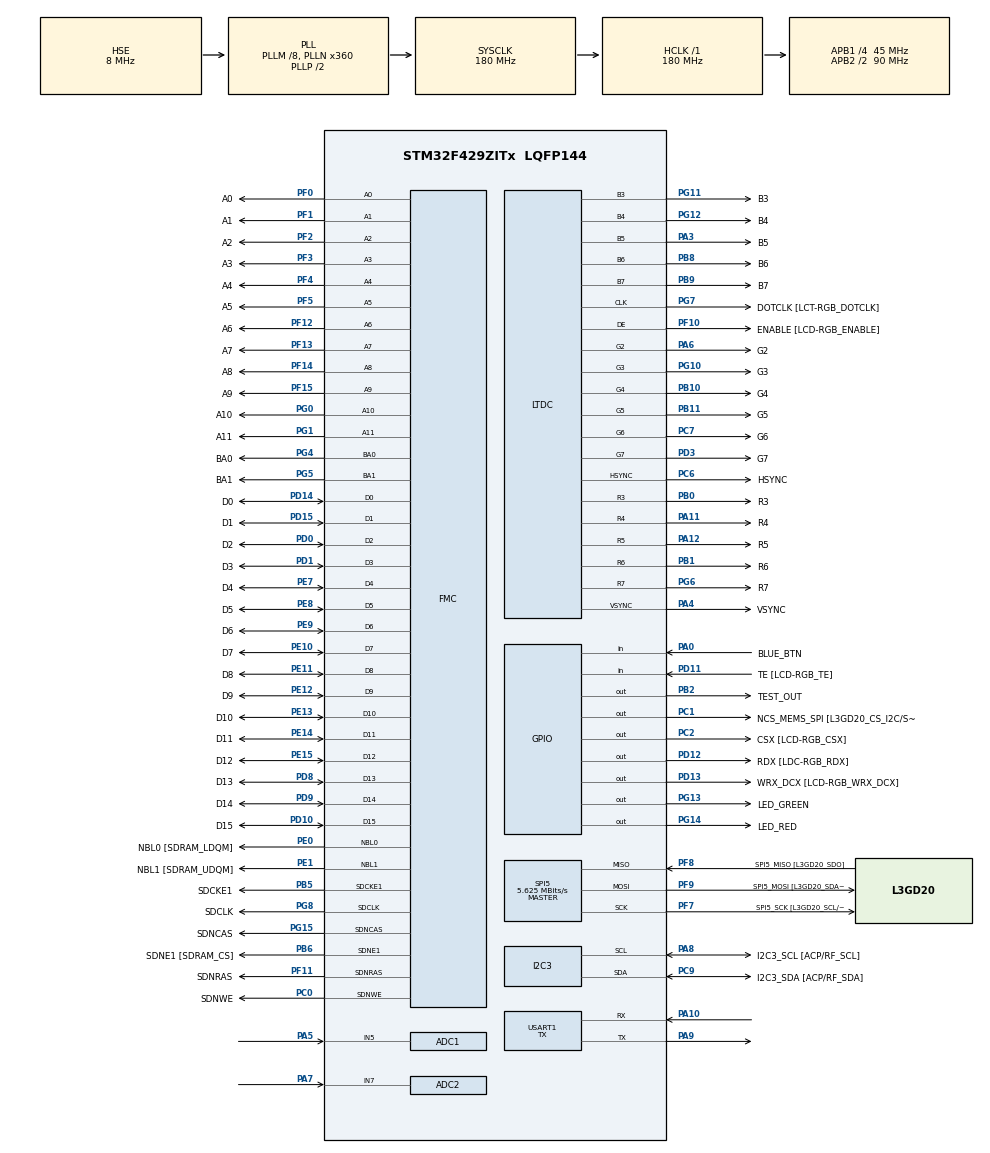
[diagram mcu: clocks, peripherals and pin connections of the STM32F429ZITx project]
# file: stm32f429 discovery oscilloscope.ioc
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PF5.GPIO_PuPd=GPIO_NOPULL
VP_TIM5_VS_ClockSourceINT.Mode=Internal
PD12.GPIO_Label=RDX [LDC-RGB_RDX]
PC10.GPIO_PuPd=GPIO_NOPULL
FMC.SDClockPeriod2=FMC_SDRAM_CLOCK_PERIOD_2
FMC.SDClockPeriod1=FMC_SDRAM_CLOCK_PERIOD_2
SH.FMC_A0.0=FMC_A0,12b-sda1
PB10.GPIO_PuPd=GPIO_NOPULL
PG8.Signal=FMC_SDCLK
PG0.Signal=FMC_A10
PA3.GPIO_PuPd=GPIO_NOPULL
PE10.GPIO_PuPd=GPIO_NOPULL
PD10.GPIO_PuPd=GPIO_NOPULL
SH.FMC_D5_DA5.0=FMC_D5,sd-16b-d1
PF10.GPIO_PuPd=GPIO_NOPULL
PG10.GPIO_PuPd=GPIO_NOPULL
PA6.GPIO_Mode=GPIO_MODE_AF_PP
SH.FMC_D9_DA9.0=FMC_D9,sd-16b-d1
PG13.GPIO_Mode=GPIO_MODE_OUTPUT_PP
PE13.GPIO_Mode=GPIO_MODE_AF_PP
PF13.GPIO_Mode=GPIO_MODE_AF_PP
PG15.GPIO_Label=SDNCAS
PA4.Mode=RGB565
PF7.Signal=SPI5_SCK
PD13.GPIO_Mode=GPIO_MODE_OUTPUT_PP
NVIC.DMA2D_IRQn=true\:5\:0\:true\:false\:true\:true\:true
SH.FMC_SDNWE.0=FMC_SDNWE,12b-sda1
SH.FMC_D11_DA11.0=FMC_D11,sd-16b-d1
PG7.GPIO_Mode=GPIO_MODE_AF_PP
RCC.APB2TimFreq_Value=180000000
PB6.Signal=FMC_SDNE1
Dma.ADC1.0.Direction=DMA_PERIPH_TO_MEMORY
PC7.Signal=LTDC_G6
PD0.Signal=FMC_D2_DA2
PD8.Signal=FMC_D13_DA13
PE1.Signal=FMC_NBL1
ADC2.EOCSelection=ADC_EOC_SEQ_CONV
Dma.ADC1.0.MemDataAlignment=DMA_MDATAALIGN_WORD
PF1.GPIO_Label=A1
PC1.GPIO_PuPd=GPIO_NOPULL
PD1.GPIO_Label=D3
FMC.SelfRefreshTime1=4
PF12.GPIO_Label=A6
LTDC.PixelFormat_L0=LTDC_PIXEL_FORMAT_RGB565
LTDC.PixelFormat_L1=LTDC_PIXEL_FORMAT_RGB565
PB1.GPIO_Speed=GPIO_SPEED_FREQ_LOW
PE9.Signal=FMC_D6_DA6
PD1.GPIO_Speed=GPIO_SPEED_FREQ_VERY_HIGH
SH.FMC_A2.0=FMC_A2,12b-sda1
PB1.GPIO_Label=R6
PG4.GPIO_Label=BA0
PC9.Mode=I2C
PD14.GPIO_PuPd=GPIO_NOPULL
PA8.Signal=I2C3_SCL
SH.FMC_D1_DA1.0=FMC_D1,sd-16b-d1
PF1.GPIO_Speed=GPIO_SPEED_FREQ_VERY_HIGH
PF1.GPIO_Mode=GPIO_MODE_AF_PP
LTDC.HSync=10
PF14.GPIO_PuPd=GPIO_NOPULL
PG0.GPIO_PuPd=GPIO_NOPULL
PE9.GPIO_Mode=GPIO_MODE_AF_PP
Mcu.Package=LQFP144
PB9.Signal=LTDC_B7
PB1.Signal=LTDC_R6
PD12.Signal=GPIO_Output
ADC2.Channel-1\#ChannelRegularConversion=ADC_CHANNEL_7
PA10.Signal=USART1_RX
PB9.GPIO_PuPd=GPIO_NOPULL
PE12.GPIO_Label=D9
FMC.WriteRecoveryTime1=3
PE12.GPIO_Speed=GPIO_SPEED_FREQ_VERY_HIGH
PB5.GPIO_Speed=GPIO_SPEED_FREQ_VERY_HIGH
SPI5.CalculateBaudRate=5.625 MBits/s
PE8.GPIO_Speed=GPIO_SPEED_FREQ_VERY_HIGH
PG8.GPIO_Speed=GPIO_SPEED_FREQ_VERY_HIGH
RCC.APB2CLKDivider=RCC_HCLK_DIV2
LTDC.VSync=2
PF5.GPIO_Speed=GPIO_SPEED_FREQ_VERY_HIGH
RCC.APB1TimFreq_Value=90000000
FMC.RowCycleDelay2=7
PF10.Mode=RGB565
FMC.RowCycleDelay1=7
PD3.GPIO_PuPd=GPIO_NOPULL
PF9.GPIO_PuPd=GPIO_NOPULL
PA4.GPIO_Label=VSYNC
PA8.GPIO_Speed=GPIO_SPEED_FREQ_LOW
ADC1.EOCSelection=ADC_EOC_SEQ_CONV
PD15.Signal=FMC_D1_DA1
ADC2.DMAAccessMode=ADC_DMAACCESSMODE_2
PG12.Signal=LTDC_B4
PB5.GPIO_Mode=GPIO_MODE_AF_PP
SH.FMC_A4.0=FMC_A4,12b-sda1
PF4.GPIO_Mode=GPIO_MODE_AF_PP
PG5.Signal=FMC_A15_BA1
SH.FMC_D10_DA10.0=FMC_D10,sd-16b-d1
PB6.GPIO_PuPd=GPIO_NOPULL
PD3.Signal=LTDC_G7
PC2.Signal=GPIO_Output
PF5.GPIO_Mode=GPIO_MODE_AF_PP
LTDC.ImageWidth_L1=240
PG8.GPIO_PuPd=GPIO_NOPULL
PF8.GPIO_Label=SPI5_MISO [L3GD20_SDO]
LTDC.ImageWidth_L0=240
PD10.Signal=FMC_D15_DA15
PA3.Mode=RGB565
PC10.GPIO_Mode=GPIO_MODE_AF_PP
PB8.GPIO_Label=B6
PB10.GPIO_Mode=GPIO_MODE_AF_PP
PA8.GPIO_Label=I2C3_SCL [ACP/RF_SCL]
PE8.GPIO_Label=D5
Dma.ADC1.0.Priority=DMA_PRIORITY_VERY_HIGH
PB1.GPIO_Mode=GPIO_MODE_AF_PP
PG10.GPIO_Mode=GPIO_MODE_AF_PP
PA5.Signal=ADCx_IN5
PF10.GPIO_Mode=GPIO_MODE_AF_PP
PE1.GPIO_Label=NBL1 [SDRAM_UDQM]
PF15.GPIO_Speed=GPIO_SPEED_FREQ_VERY_HIGH
PF13.GPIO_PuPd=GPIO_NOPULL
FMC.ReadBurst1=FMC_SDRAM_RBURST_DISABLE
SH.FMC_A6.0=FMC_A6,12b-sda1
PE14.Signal=FMC_D11_DA11
PF12.GPIO_Speed=GPIO_SPEED_FREQ_VERY_HIGH
PG7.GPIO_Label=DOTCLK [LCT-RGB_DOTCLK]
PF4.GPIO_Label=A4
PC9.GPIO_PuPd=GPIO_NOPULL
PC1.GPIO_Speed=GPIO_SPEED_FREQ_LOW
PF13.Signal=FMC_A7
PG14.GPIO_PuPd=GPIO_NOPULL
PG1.GPIO_Speed=GPIO_SPEED_FREQ_VERY_HIGH
ADC1.ExternalTrigConv=ADC_EXTERNALTRIGCONV_T2_TRGO
PC7.GPIO_Label=G6
ADC1.master=1
ADC2.NbrOfConversionFlag=1
PB5.GPIO_PuPd=GPIO_NOPULL
ProjectManager.HeapSize=0x10
PB1.Mode=RGB565
PD0.GPIO_PuPd=GPIO_NOPULL
PG12.GPIO_Speed=GPIO_SPEED_FREQ_LOW
PD8.GPIO_Speed=GPIO_SPEED_FREQ_VERY_HIGH
NVIC.PriorityGroup=NVIC_PRIORITYGROUP_4
PF0.GPIO_Label=A0
PE15.GPIO_Speed=GPIO_SPEED_FREQ_VERY_HIGH
PF4.Signal=FMC_A4
PD14.GPIO_Mode=GPIO_MODE_AF_PP
PG5.GPIO_Speed=GPIO_SPEED_FREQ_VERY_HIGH
Mcu.Family=STM32F4
LTDC.BlendingFactor1_L1=LTDC_BLENDING_FACTOR1_PAxCA
LTDC.BlendingFactor1_L0=LTDC_BLENDING_FACTOR1_CA
PA6.Mode=RGB565
SH.FMC_A8.0=FMC_A8,12b-sda1
SH.FMC_D14_DA14.0=FMC_D14,sd-16b-d1
PE11.GPIO_Label=D8
PD9.GPIO_Speed=GPIO_SPEED_FREQ_VERY_HIGH
PD0.GPIO_Label=D2
PA11.Mode=RGB565
PF9.GPIO_Speed=GPIO_SPEED_FREQ_LOW
PC2.GPIO_Speed=GPIO_SPEED_FREQ_LOW
SH.FMC_A14_BA0.0=FMC_BA0,FourSdramBanks1
SH.FMC_A11.0=FMC_A11,12b-sda1
PD8.GPIO_PuPd=GPIO_NOPULL
PG5.GPIO_Label=BA1
PG11.Signal=LTDC_B3
PG15.Signal=FMC_SDNCAS
PD13.Signal=GPIO_Output
PE11.GPIO_PuPd=GPIO_NOPULL
PF11.GPIO_PuPd=GPIO_NOPULL
ADC1.Mode=ADC_DUALMODE_REGSIMULT
PB1.GPIO_PuPd=GPIO_NOPULL
PF13.GPIO_Speed=GPIO_SPEED_FREQ_VERY_HIGH
LTDC.WindowX1_L1=240
SH.FMC_NBL1.0=FMC_NBL1,Sd2ByteEnable1
LTDC.WindowX1_L0=240
PG5.GPIO_PuPd=GPIO_NOPULL
ADC1.Channel-0\#ChannelRegularConversion=ADC_CHANNEL_5
RCC.HSE_VALUE=8000000
PA4.GPIO_PuPd=GPIO_NOPULL
FMC.ExitSelfRefreshDelay1=7
PF7.GPIO_Mode=GPIO_MODE_AF_PP
PE13.GPIO_PuPd=GPIO_NOPULL
PA4.GPIO_Speed=GPIO_SPEED_FREQ_LOW
PG11.GPIO_Speed=GPIO_SPEED_FREQ_LOW
PH1/OSC_OUT.GPIO_Label=PH1-OSC_OUT
PA6.GPIO_PuPd=GPIO_NOPULL
PF9.Mode=Full_Duplex_Master
PF7.GPIO_Speed=GPIO_SPEED_FREQ_LOW
PF8.GPIO_PuPd=GPIO_NOPULL
PF11.Signal=FMC_SDNRAS
PB5.Mode=SdramChipSelect2_1
PC7.GPIO_Mode=GPIO_MODE_AF_PP
PG7.GPIO_PuPd=GPIO_NOPULL
PD10.GPIO_Speed=GPIO_SPEED_FREQ_VERY_HIGH
PG4.GPIO_Mode=GPIO_MODE_AF_PP
PD6.GPIO_Mode=GPIO_MODE_AF_PP
PD13.GPIO_Label=WRX_DCX [LCD-RGB_WRX_DCX]
PA6.Signal=LTDC_G2
PB0.GPIO_Mode=GPIO_MODE_AF_PP
RCC.EnbaleCSS=true
PG1.GPIO_PuPd=GPIO_NOPULL
PF8.Signal=SPI5_MISO
PG0.GPIO_Label=A10
PB5.GPIO_Label=SDCKE1
PD0.GPIO_Mode=GPIO_MODE_AF_PP
PG14.GPIO_Mode=GPIO_MODE_OUTPUT_PP
PG11.GPIO_Label=B3
PD3.GPIO_Label=G7
PE14.GPIO_Mode=GPIO_MODE_AF_PP
PE7.Signal=FMC_D4_DA4
PD6.Signal=LTDC_B2
Dma.Request0=ADC1
PF3.GPIO_Label=A3
PA12.GPIO_Speed=GPIO_SPEED_FREQ_LOW
PA3.Signal=LTDC_B5
PE0.GPIO_PuPd=GPIO_NOPULL
PG1.GPIO_Mode=GPIO_MODE_AF_PP
NVIC.LTDC_IRQn=true\:5\:0\:true\:false\:true\:true\:true
LTDC.VFP=4
PD15.GPIO_Label=D1
LTDC.WindowY1_L0=320
PG7.Signal=LTDC_CLK
LTDC.WindowY1_L1=320
PA10.Mode=Asynchronous
PC9.GPIO_Label=I2C3_SDA [ACP/RF_SDA]
PF10.GPIO_Speed=GPIO_SPEED_FREQ_LOW
PE14.GPIO_Label=D11
PD9.Signal=FMC_D14_DA14
SPI5.Mode=SPI_MODE_MASTER
PA12.GPIO_Label=R5
PD8.GPIO_Label=D13
PB0.GPIO_Speed=GPIO_SPEED_FREQ_LOW
PG8.GPIO_Label=SDCLK
Dma.ADC1.0.PeriphDataAlignment=DMA_PDATAALIGN_WORD
PA9.Mode=Asynchronous
PB2/BOOT1.Signal=GPIO_Output
PB10.GPIO_Label=G4
PC9.GPIO_Mode=GPIO_MODE_AF_OD
SH.FMC_D13_DA13.0=FMC_D13,sd-16b-d1
PA3.GPIO_Mode=GPIO_MODE_AF_PP
PG0.GPIO_Speed=GPIO_SPEED_FREQ_VERY_HIGH
PB9.Mode=RGB565
PF9.GPIO_Label=SPI5_MOSI [L3GD20_SDA/SDI/SDO]
PD10.GPIO_Label=D15
PE10.GPIO_Mode=GPIO_MODE_AF_PP
board=STM32F429I-DISC1
PD13.GPIO_Speed=GPIO_SPEED_FREQ_LOW
PG12.Mode=RGB565
PC7.GPIO_Speed=GPIO_SPEED_FREQ_LOW
RCC.VCOOutputFreq_Value=360000000
ADC1.EnableAnalogWatchDog=true
PA4.GPIO_Mode=GPIO_MODE_AF_PP
PF4.GPIO_Speed=GPIO_SPEED_FREQ_VERY_HIGH
PC1.GPIO_Label=NCS_MEMS_SPI [L3GD20_CS_I2C/SPI]
PE11.GPIO_Mode=GPIO_MODE_AF_PP
SH.FMC_D12_DA12.0=FMC_D12,sd-16b-d1
PF15.GPIO_Label=A9
PE14.GPIO_PuPd=GPIO_NOPULL
PF1.Signal=FMC_A1
PF8.GPIO_Mode=GPIO_MODE_AF_PP
PE0.Signal=FMC_NBL0
PE7.GPIO_Label=D4
PE12.Signal=FMC_D9_DA9
PE12.GPIO_Mode=GPIO_MODE_AF_PP
RCC.48MHZClocksFreq_Value=120000000
RCC.SYSCLKFreq_VALUE=180000000
TIM5.Prescaler=99
Dma.ADC1.0.MemInc=DMA_MINC_ENABLE
PE15.GPIO_PuPd=GPIO_NOPULL
PG4.GPIO_PuPd=GPIO_NOPULL
PD3.GPIO_Mode=GPIO_MODE_AF_PP
RCC.HSI_VALUE=16000000
PA8.GPIO_PuPd=GPIO_NOPULL
PH0/OSC_IN.GPIO_Label=PH0-OSC_IN
PF9.GPIO_Mode=GPIO_MODE_AF_PP
RCC.PLLQ=3
RCC.PLLM=8
RCC.PLLN=360
ADC2.Rank-1\#ChannelRegularConversion=1
TIM5.Period=44
PG0.GPIO_Mode=GPIO_MODE_AF_PP
PB8.GPIO_Speed=GPIO_SPEED_FREQ_LOW
PD6.GPIO_Speed=GPIO_SPEED_FREQ_LOW
PG14.GPIO_Speed=GPIO_SPEED_FREQ_LOW
LTDC.ImageHeight_L0=320
LTDC.ImageHeight_L1=320
PB0.GPIO_PuPd=GPIO_NOPULL
PA3.GPIO_Label=B5
PD6.GPIO_PuPd=GPIO_NOPULL
PA11.GPIO_Speed=GPIO_SPEED_FREQ_LOW
PF15.GPIO_Mode=GPIO_MODE_AF_PP
SH.FMC_D7_DA7.0=FMC_D7,sd-16b-d1
PE15.GPIO_Mode=GPIO_MODE_AF_PP
PD1.GPIO_Mode=GPIO_MODE_AF_PP
PD15.GPIO_Mode=GPIO_MODE_AF_PP
PE14.GPIO_Speed=GPIO_SPEED_FREQ_VERY_HIGH
FMC.RCDDelay1=2
ADC2.SamplingTime-1\#ChannelRegularConversion=ADC_SAMPLETIME_3CYCLES
PB10.Mode=RGB565
PA8.GPIO_Mode=GPIO_MODE_AF_OD
PG4.Signal=FMC_A14_BA0
PG6.GPIO_Label=R7
PE8.GPIO_PuPd=GPIO_NOPULL
FMC.LoadToActiveDelay1=2
PC6.GPIO_Label=HSYNC
PA6.GPIO_Label=G2
PB6.GPIO_Label=SDNE1 [SDRAM_CS]
PA3.GPIO_Speed=GPIO_SPEED_FREQ_LOW
PD3.GPIO_Speed=GPIO_SPEED_FREQ_LOW
PG6.Mode=RGB565
PD6.GPIO_Label=B2
PG13.Signal=GPIO_Output
RCC.SYSCLKSource=RCC_SYSCLKSOURCE_PLLCLK
PG15.GPIO_Mode=GPIO_MODE_AF_PP
PB11.GPIO_Speed=GPIO_SPEED_FREQ_LOW
SH.FMC_A15_BA1.0=FMC_BA1,FourSdramBanks1
PD14.GPIO_Speed=GPIO_SPEED_FREQ_VERY_HIGH
NVIC.TIM5_IRQn=true\:0\:0\:false\:false\:true\:true\:true
PB2/BOOT1.GPIO_Label=TEST_OUT
PH1/OSC_OUT.Signal=RCC_OSC_OUT
PB6.Mode=SdramChipSelect2_1
PF10.GPIO_Label=ENABLE [LCD-RGB_ENABLE]
PF14.GPIO_Speed=GPIO_SPEED_FREQ_VERY_HIGH
PG6.GPIO_PuPd=GPIO_NOPULL
PF11.GPIO_Mode=GPIO_MODE_AF_PP
Dma.ADC1.0.PeriphInc=DMA_PINC_DISABLE
PD11.GPIO_Mode=GPIO_MODE_INPUT
PF8.Mode=Full_Duplex_Master
PF3.Signal=FMC_A3
PD3.Mode=RGB565
PE10.Signal=FMC_D7_DA7
ADC1.SamplingTime-0\#ChannelRegularConversion=ADC_SAMPLETIME_3CYCLES
PF3.GPIO_Speed=GPIO_SPEED_FREQ_VERY_HIGH
PF3.GPIO_PuPd=GPIO_NOPULL
PC6.GPIO_PuPd=GPIO_NOPULL
SH.FMC_A1.0=FMC_A1,12b-sda1
SH.FMC_SDCLK.0=FMC_SDCLK,12b-sda1
PC2.GPIO_Mode=GPIO_MODE_OUTPUT_PP
PG12.GPIO_PuPd=GPIO_NOPULL
PF14.Signal=FMC_A8
VP_DMA2D_VS_DMA2D.Mode=DMA2D_Activate
Dma.ADC1.0.FIFOMode=DMA_FIFOMODE_DISABLE
PA6.GPIO_Speed=GPIO_SPEED_FREQ_LOW
PB11.GPIO_Mode=GPIO_MODE_AF_PP
PA12.GPIO_PuPd=GPIO_NOPULL
PE10.GPIO_Label=D7
PD9.GPIO_PuPd=GPIO_NOPULL
PC6.GPIO_Speed=GPIO_SPEED_FREQ_LOW
SH.FMC_D3_DA3.0=FMC_D3,sd-16b-d1
SPI5.VirtualType=VM_MASTER
PG6.GPIO_Speed=GPIO_SPEED_FREQ_LOW
PE12.GPIO_PuPd=GPIO_NOPULL
PD8.GPIO_Mode=GPIO_MODE_AF_PP
Dma.ADC1.0.Instance=DMA2_Stream0
ADC1.Rank-0\#ChannelRegularConversion=1
PD9.GPIO_Label=D14
PE11.GPIO_Speed=GPIO_SPEED_FREQ_VERY_HIGH
PD9.GPIO_Mode=GPIO_MODE_AF_PP
PB8.GPIO_PuPd=GPIO_NOPULL
PC6.Signal=LTDC_HSYNC
PB11.GPIO_Label=G5
PD1.Signal=FMC_D3_DA3
PA11.GPIO_Label=R4
PE1.GPIO_PuPd=GPIO_NOPULL
PF14.GPIO_Label=A8
PD1.GPIO_PuPd=GPIO_NOPULL
PC0.Signal=FMC_SDNWE
RCC.APB1CLKDivider=RCC_HCLK_DIV4
PF13.GPIO_Label=A7
PG13.GPIO_Label=LED_GREEN
PD0.GPIO_Speed=GPIO_SPEED_FREQ_VERY_HIGH
PG10.Signal=LTDC_G3
PE0.GPIO_Speed=GPIO_SPEED_FREQ_VERY_HIGH
PF11.GPIO_Speed=GPIO_SPEED_FREQ_VERY_HIGH
SH.FMC_A3.0=FMC_A3,12b-sda1
TIM5.TIM_MasterOutputTrigger=TIM_TRGO_UPDATE
FMC.CASLatency1=FMC_SDRAM_CAS_LATENCY_3
PF2.GPIO_Mode=GPIO_MODE_AF_PP
PB11.Mode=RGB565
SH.FMC_D15_DA15.0=FMC_D15,sd-16b-d1
SH.ADCx_IN7.0=ADC2_IN7,IN7
PC6.Mode=RGB565
PA9.Signal=USART1_TX
PC7.GPIO_PuPd=GPIO_NOPULL
PE9.GPIO_Label=D6
PB10.Signal=LTDC_G4
PE7.GPIO_Speed=GPIO_SPEED_FREQ_VERY_HIGH
PE15.Signal=FMC_D12_DA12
PG11.GPIO_Mode=GPIO_MODE_AF_PP
USART1.Mode=MODE_TX
PE8.Signal=FMC_D5_DA5
PG5.GPIO_Mode=GPIO_MODE_AF_PP
PA0/WKUP.GPIO_Label=BLUE_BTN
PC6.GPIO_Mode=GPIO_MODE_AF_PP
ADC1.DMAContinuousRequests=ENABLE
PG14.GPIO_Label=LED_RED
SH.FMC_SDNCAS.0=FMC_SDNCAS,12b-sda1
PG12.GPIO_Mode=GPIO_MODE_AF_PP
PF7.GPIO_PuPd=GPIO_NOPULL
PA4.Signal=LTDC_VSYNC
PB5.Signal=FMC_SDCKE1
PE13.GPIO_Label=D10
PD11.Signal=GPIO_Input
USART1.VirtualMode=VM_ASYNC
SH.FMC_A5.0=FMC_A5,12b-sda1
PG11.Mode=RGB565
LTDC.Alpha_L0=255
PA11.Signal=LTDC_R4
PF9.Signal=SPI5_MOSI
SH.ADCx_IN5.0=ADC1_IN5,IN5
PC9.GPIO_Speed=GPIO_SPEED_FREQ_LOW
PB8.Mode=RGB565
PF12.GPIO_PuPd=GPIO_NOPULL
TIM2.AutoReloadPreload=TIM_AUTORELOAD_PRELOAD_ENABLE
PA8.Mode=I2C
PB6.GPIO_Speed=GPIO_SPEED_FREQ_VERY_HIGH
PG6.GPIO_Mode=GPIO_MODE_AF_PP
PB0.Signal=LTDC_R3
PE0.GPIO_Mode=GPIO_MODE_AF_PP
PC1.Signal=GPIO_Output
PF3.GPIO_Mode=GPIO_MODE_AF_PP
PG10.GPIO_Label=G3
PG15.GPIO_PuPd=GPIO_NOPULL
PE7.GPIO_PuPd=GPIO_NOPULL
RCC.CortexFreq_Value=180000000
PG6.Signal=LTDC_R7
PB10.GPIO_Speed=GPIO_SPEED_FREQ_LOW
PB6.GPIO_Mode=GPIO_MODE_AF_PP
RCC.PLLSAIDivR=RCC_PLLSAIDIVR_8
LTDC.HBP=20
PD15.GPIO_Speed=GPIO_SPEED_FREQ_VERY_HIGH
PC10.Signal=LTDC_R2
PF4.GPIO_PuPd=GPIO_NOPULL
SH.FMC_NBL0.0=FMC_NBL0,Sd2ByteEnable1
SH.FMC_D6_DA6.0=FMC_D6,sd-16b-d1
PC0.GPIO_Label=SDNWE
PE9.GPIO_Speed=GPIO_SPEED_FREQ_VERY_HIGH
PA0/WKUP.Signal=GPIO_Input
PB0.GPIO_Label=R3
PC10.GPIO_Speed=GPIO_SPEED_FREQ_LOW
PA11.GPIO_PuPd=GPIO_NOPULL
PB11.GPIO_PuPd=GPIO_NOPULL
PB11.Signal=LTDC_G5
PG8.GPIO_Mode=GPIO_MODE_AF_PP
PF2.GPIO_Speed=GPIO_SPEED_FREQ_VERY_HIGH
ProjectManager.StackSize=0x10
PD11.GPIO_PuPd=GPIO_NOPULL
SH.FMC_A7.0=FMC_A7,12b-sda1
PA12.Signal=LTDC_R5
PE1.GPIO_Mode=GPIO_MODE_AF_PP
PH0/OSC_IN.Mode=HSE-External-Oscillator
PG11.GPIO_PuPd=GPIO_NOPULL
PD11.GPIO_Label=TE [LCD-RGB_TE]
RCC.HCLKFreq_Value=180000000
PF11.GPIO_Label=SDNRAS
PF2.GPIO_PuPd=GPIO_NOPULL
PF12.Signal=FMC_A6
NVIC.DMA2_Stream0_IRQn=true\:0\:0\:false\:false\:true\:false\:true
SH.FMC_A10.0=FMC_A10,12b-sda1
RCC.AHBFreq_Value=180000000
PC1.GPIO_Mode=GPIO_MODE_OUTPUT_PP
SH.FMC_D8_DA8.0=FMC_D8,sd-16b-d1
FMC.RPDelay2=2
FMC.RPDelay1=2
PG13.GPIO_PuPd=GPIO_NOPULL
SH.FMC_D2_DA2.0=FMC_D2,sd-16b-d1
PE13.Signal=FMC_D10_DA10
PF7.GPIO_Label=SPI5_SCK [L3GD20_SCL/SPC]
PG4.GPIO_Speed=GPIO_SPEED_FREQ_VERY_HIGH
LTDC.HFP=10
LTDC.BlendingFactor2_L0=LTDC_BLENDING_FACTOR2_CA
LTDC.BlendingFactor2_L1=LTDC_BLENDING_FACTOR2_PAxCA
FMC.ReadPipeDelay1=FMC_SDRAM_RPIPE_DELAY_1
FMC.ReadPipeDelay2=FMC_SDRAM_RPIPE_DELAY_1
PE10.GPIO_Speed=GPIO_SPEED_FREQ_VERY_HIGH
SH.FMC_SDNRAS.0=FMC_SDNRAS,12b-sda1
DMA2D.ColorMode=DMA2D_OUTPUT_RGB565
LTDC.ActiveW=240
PH1/OSC_OUT.Mode=HSE-External-Oscillator
PF12.GPIO_Mode=GPIO_MODE_AF_PP
PD12.GPIO_Mode=GPIO_MODE_OUTPUT_PP
SPI5.BaudRatePrescaler=SPI_BAUDRATEPRESCALER_16
SH.FMC_D0_DA0.0=FMC_D0,sd-16b-d1
PG15.GPIO_Speed=GPIO_SPEED_FREQ_VERY_HIGH
PF15.GPIO_PuPd=GPIO_NOPULL
PD15.GPIO_PuPd=GPIO_NOPULL
PF5.GPIO_Label=A5
SH.FMC_A9.0=FMC_A9,12b-sda1
SH.FMC_D4_DA4.0=FMC_D4,sd-16b-d1
PE8.GPIO_Mode=GPIO_MODE_AF_PP
PE0.GPIO_Label=NBL0 [SDRAM_LDQM]
RCC.PLLSAIN=192
PF5.Signal=FMC_A5
RCC.PLLSAIR=4
TIM2.TIM_MasterOutputTrigger=TIM_TRGO_UPDATE
PB9.GPIO_Speed=GPIO_SPEED_FREQ_LOW
PG13.GPIO_Speed=GPIO_SPEED_FREQ_LOW
PF0.Signal=FMC_A0
PC0.GPIO_PuPd=GPIO_NOPULL
PC2.GPIO_Label=CSX [LCD-RGB_CSX]
PF0.GPIO_Mode=GPIO_MODE_AF_PP
ADC2.ClockPrescaler=ADC_CLOCK_SYNC_PCLK_DIV4
RCC.PLLSourceVirtual=RCC_PLLSOURCE_HSE
I2C3.I2C_Mode=I2C_Fast
LTDC.FBStartAdress_L0=0xD0000000
LTDC.FBStartAdress_L1=0xD0025800
PD12.GPIO_Speed=GPIO_SPEED_FREQ_LOW
ADC2.Mode=ADC_DUALMODE_REGSIMULT
PB9.GPIO_Label=B7
PC10.GPIO_Label=R2
PG1.Signal=FMC_A11
PG10.Mode=RGB565
PG10.GPIO_Speed=GPIO_SPEED_FREQ_LOW
PF0.GPIO_Speed=GPIO_SPEED_FREQ_VERY_HIGH
PD10.GPIO_Mode=GPIO_MODE_AF_PP
PF7.Mode=Full_Duplex_Master
PC0.GPIO_Speed=GPIO_SPEED_FREQ_VERY_HIGH
PE15.GPIO_Label=D12
ProjectManager.TargetToolchain=STM32CubeIDE
Dma.ADC1.0.Mode=DMA_CIRCULAR
LTDC.ActiveH=320
PF2.Signal=FMC_A2
PE11.Signal=FMC_D8_DA8
PG7.Mode=RGB565
RCC.LSE_VALUE=32768
PE7.GPIO_Mode=GPIO_MODE_AF_PP
PG14.Signal=GPIO_Output
PB0.Mode=RGB565
PG1.GPIO_Label=A11
PB9.GPIO_Mode=GPIO_MODE_AF_PP
PA12.GPIO_Mode=GPIO_MODE_AF_PP
PH0/OSC_IN.Signal=RCC_OSC_IN
PG7.GPIO_Speed=GPIO_SPEED_FREQ_LOW
RCC.APB2Freq_Value=90000000
PC0.GPIO_Mode=GPIO_MODE_AF_PP
LTDC.Layers=1
VP_TIM2_VS_ClockSourceINT.Mode=Internal
PF10.Signal=LTDC_DE
PE1.GPIO_Speed=GPIO_SPEED_FREQ_VERY_HIGH
PF1.GPIO_PuPd=GPIO_NOPULL
PD13.GPIO_PuPd=GPIO_NOPULL
PF15.Signal=FMC_A9
PD14.GPIO_Label=D0
PC2.GPIO_PuPd=GPIO_NOPULL
Mcu.Name=STM32F429ZITx
PD14.Signal=FMC_D0_DA0
PF0.GPIO_PuPd=GPIO_NOPULL
PA12.Mode=RGB565
PG12.GPIO_Label=B4
ADC1.WatchdogChannel=ADC_CHANNEL_5
ADC1.NbrOfConversionFlag=1
PF8.GPIO_Speed=GPIO_SPEED_FREQ_LOW
PE13.GPIO_Speed=GPIO_SPEED_FREQ_VERY_HIGH
PB8.Signal=LTDC_B6
PF14.GPIO_Mode=GPIO_MODE_AF_PP
PC9.Signal=I2C3_SDA
PC7.Mode=RGB565
PA11.GPIO_Mode=GPIO_MODE_AF_PP
PB8.GPIO_Mode=GPIO_MODE_AF_PP
RCC.APB1Freq_Value=45000000
ADC1.ClockPrescaler=ADC_CLOCK_SYNC_PCLK_DIV4
PD12.GPIO_PuPd=GPIO_NOPULL
SPI5.Direction=SPI_DIRECTION_2LINES
PA7.Signal=ADCx_IN7
PE9.GPIO_PuPd=GPIO_NOPULL
PF2.GPIO_Label=A2

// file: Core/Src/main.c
/* USER CODE BEGIN Header */
/**
  ******************************************************************************
  * @file           : main.c
  * @brief          : Main program body
  ******************************************************************************
  * @attention
  *
  * <h2><center>&copy; Copyright (c) 2020 STMicroelectronics.
  * All rights reserved.</center></h2>
  *
  * This software component is licensed by ST under Ultimate Liberty license
  * SLA0044, the "License"; You may not use this file except in compliance with
  * the License. You may obtain a copy of the License at:
  *                             www.st.com/SLA0044
  *
  ******************************************************************************
  */
/* USER CODE END Header */
#include "main.h"

/* USER CODE BEGIN Includes */
#include "oszi.h"
#include "stm32_ub_sdram.h"
/* USER CODE END Includes */

ADC_HandleTypeDef hadc1;
ADC_HandleTypeDef hadc2;
DMA_HandleTypeDef hdma_adc1;

DMA2D_HandleTypeDef hdma2d;

I2C_HandleTypeDef hi2c3;

LTDC_HandleTypeDef hltdc;

SPI_HandleTypeDef hspi5;

TIM_HandleTypeDef htim2;
TIM_HandleTypeDef htim5;

UART_HandleTypeDef huart1;

SDRAM_HandleTypeDef hsdram1;

void SystemClock_Config(void);
static void MX_GPIO_Init(void);
static void MX_DMA_Init(void);
static void MX_DMA2D_Init(void);
static void MX_FMC_Init(void);
static void MX_I2C3_Init(void);
static void MX_LTDC_Init(void);
static void MX_ADC1_Init(void);
static void MX_ADC2_Init(void);
static void MX_TIM2_Init(void);
static void MX_SPI5_Init(void);
static void MX_TIM5_Init(void);
static void MX_USART1_UART_Init(void);

int main(void)
{
  /* USER CODE BEGIN 1 */

	// For freezing the timers when debugging (If the core halts, also do the timers)
	 __HAL_DBGMCU_FREEZE_TIM2();
	 __HAL_DBGMCU_FREEZE_TIM5();
  /* USER CODE END 1 */

  /* MCU Configuration--------------------------------------------------------*/

  /* Reset of all peripherals, Initializes the Flash interface and the Systick. */
  HAL_Init();

  /* Configure the system clock */
  SystemClock_Config();

  /* Initialize all configured peripherals */
  MX_GPIO_Init();
  MX_DMA_Init();
  MX_DMA2D_Init();
  MX_FMC_Init();
  MX_I2C3_Init();
  MX_LTDC_Init();
  MX_ADC1_Init();
  MX_ADC2_Init();
  MX_TIM2_Init();
  MX_SPI5_Init();
  MX_TIM5_Init();
  MX_USART1_UART_Init();
  /* USER CODE BEGIN 2 */
  oszi_init();
  oszi_start();
  /* USER CODE END 2 */

  /* Infinite loop */
  while (1)
{

  }
}

void SystemClock_Config(void)
{
  RCC_OscInitTypeDef RCC_OscInitStruct = {0};
  RCC_ClkInitTypeDef RCC_ClkInitStruct = {0};
  RCC_PeriphCLKInitTypeDef PeriphClkInitStruct = {0};

  /** Configure the main internal regulator output voltage
  */
  __HAL_RCC_PWR_CLK_ENABLE();
  __HAL_PWR_VOLTAGESCALING_CONFIG(PWR_REGULATOR_VOLTAGE_SCALE1);
  /** Initializes the RCC Oscillators according to the specified parameters
  * in the RCC_OscInitTypeDef structure.
  */
  RCC_OscInitStruct.OscillatorType = RCC_OSCILLATORTYPE_HSE;
  RCC_OscInitStruct.HSEState = RCC_HSE_ON;
  RCC_OscInitStruct.PLL.PLLState = RCC_PLL_ON;
  RCC_OscInitStruct.PLL.PLLSource = RCC_PLLSOURCE_HSE;
  RCC_OscInitStruct.PLL.PLLM = 8;
  RCC_OscInitStruct.PLL.PLLN = 360;
  RCC_OscInitStruct.PLL.PLLP = RCC_PLLP_DIV2;
  RCC_OscInitStruct.PLL.PLLQ = 3;
  if (HAL_RCC_OscConfig(&RCC_OscInitStruct) != HAL_OK)
  {
    Error_Handler();
  }
  /** Activate the Over-Drive mode
  */
  if (HAL_PWREx_EnableOverDrive() != HAL_OK)
  {
    Error_Handler();
  }
  /** Initializes the CPU, AHB and APB buses clocks
  */
  RCC_ClkInitStruct.ClockType = RCC_CLOCKTYPE_HCLK|RCC_CLOCKTYPE_SYSCLK
                              |RCC_CLOCKTYPE_PCLK1|RCC_CLOCKTYPE_PCLK2;
  RCC_ClkInitStruct.SYSCLKSource = RCC_SYSCLKSOURCE_PLLCLK;
  RCC_ClkInitStruct.AHBCLKDivider = RCC_SYSCLK_DIV1;
  RCC_ClkInitStruct.APB1CLKDivider = RCC_HCLK_DIV4;
  RCC_ClkInitStruct.APB2CLKDivider = RCC_HCLK_DIV2;

  if (HAL_RCC_ClockConfig(&RCC_ClkInitStruct, FLASH_LATENCY_5) != HAL_OK)
  {
    Error_Handler();
  }
  PeriphClkInitStruct.PeriphClockSelection = RCC_PERIPHCLK_LTDC;
  PeriphClkInitStruct.PLLSAI.PLLSAIN = 192;
  PeriphClkInitStruct.PLLSAI.PLLSAIR = 4;
  PeriphClkInitStruct.PLLSAIDivR = RCC_PLLSAIDIVR_8;
  if (HAL_RCCEx_PeriphCLKConfig(&PeriphClkInitStruct) != HAL_OK)
  {
    Error_Handler();
  }
  /** Enables the Clock Security System
  */
  HAL_RCC_EnableCSS();
}

static void MX_ADC1_Init(void)
{

  ADC_MultiModeTypeDef multimode = {0};
  ADC_AnalogWDGConfTypeDef AnalogWDGConfig = {0};
  ADC_ChannelConfTypeDef sConfig = {0};

  /** Configure the global features of the ADC (Clock, Resolution, Data Alignment and number of conversion)
  */
  hadc1.Instance = ADC1;
  hadc1.Init.ClockPrescaler = ADC_CLOCK_SYNC_PCLK_DIV4;
  hadc1.Init.Resolution = ADC_RESOLUTION_12B;
  hadc1.Init.ScanConvMode = DISABLE;
  hadc1.Init.ContinuousConvMode = DISABLE;
  hadc1.Init.DiscontinuousConvMode = DISABLE;
  hadc1.Init.ExternalTrigConvEdge = ADC_EXTERNALTRIGCONVEDGE_RISING;
  hadc1.Init.ExternalTrigConv = ADC_EXTERNALTRIGCONV_T2_TRGO;
  hadc1.Init.DataAlign = ADC_DATAALIGN_RIGHT;
  hadc1.Init.NbrOfConversion = 1;
  hadc1.Init.DMAContinuousRequests = ENABLE;
  hadc1.Init.EOCSelection = ADC_EOC_SEQ_CONV;
  if (HAL_ADC_Init(&hadc1) != HAL_OK)
  {
    Error_Handler();
  }
  /** Configure the ADC multi-mode
  */
  multimode.Mode = ADC_DUALMODE_REGSIMULT;
  multimode.DMAAccessMode = ADC_DMAACCESSMODE_2;
  multimode.TwoSamplingDelay = ADC_TWOSAMPLINGDELAY_5CYCLES;
  if (HAL_ADCEx_MultiModeConfigChannel(&hadc1, &multimode) != HAL_OK)
  {
    Error_Handler();
  }
  /** Configure the analog watchdog
  */
  AnalogWDGConfig.WatchdogMode = ADC_ANALOGWATCHDOG_SINGLE_REG;
  AnalogWDGConfig.HighThreshold = 0;
  AnalogWDGConfig.LowThreshold = 0;
  AnalogWDGConfig.Channel = ADC_CHANNEL_5;
  AnalogWDGConfig.ITMode = DISABLE;
  if (HAL_ADC_AnalogWDGConfig(&hadc1, &AnalogWDGConfig) != HAL_OK)
  {
    Error_Handler();
  }
  /** Configure for the selected ADC regular channel its corresponding rank in the sequencer and its sample time.
  */
  sConfig.Channel = ADC_CHANNEL_5;
  sConfig.Rank = 1;
  sConfig.SamplingTime = ADC_SAMPLETIME_3CYCLES;
  if (HAL_ADC_ConfigChannel(&hadc1, &sConfig) != HAL_OK)
  {
    Error_Handler();
  }

}

static void MX_ADC2_Init(void)
{

  ADC_ChannelConfTypeDef sConfig = {0};

  /** Configure the global features of the ADC (Clock, Resolution, Data Alignment and number of conversion)
  */
  hadc2.Instance = ADC2;
  hadc2.Init.ClockPrescaler = ADC_CLOCK_SYNC_PCLK_DIV4;
  hadc2.Init.Resolution = ADC_RESOLUTION_12B;
  hadc2.Init.ScanConvMode = DISABLE;
  hadc2.Init.ContinuousConvMode = DISABLE;
  hadc2.Init.DiscontinuousConvMode = DISABLE;
  hadc2.Init.DataAlign = ADC_DATAALIGN_RIGHT;
  hadc2.Init.NbrOfConversion = 1;
  hadc2.Init.DMAContinuousRequests = DISABLE;
  hadc2.Init.EOCSelection = ADC_EOC_SEQ_CONV;
  if (HAL_ADC_Init(&hadc2) != HAL_OK)
  {
    Error_Handler();
  }
  /** Configure for the selected ADC regular channel its corresponding rank in the sequencer and its sample time.
  */
  sConfig.Channel = ADC_CHANNEL_7;
  sConfig.Rank = 1;
  sConfig.SamplingTime = ADC_SAMPLETIME_3CYCLES;
  if (HAL_ADC_ConfigChannel(&hadc2, &sConfig) != HAL_OK)
  {
    Error_Handler();
  }

}

static void MX_DMA2D_Init(void)
{

  hdma2d.Instance = DMA2D;
  hdma2d.Init.Mode = DMA2D_M2M;
  hdma2d.Init.ColorMode = DMA2D_OUTPUT_RGB565;
  hdma2d.Init.OutputOffset = 0;
  hdma2d.LayerCfg[1].InputOffset = 0;
  hdma2d.LayerCfg[1].InputColorMode = DMA2D_INPUT_RGB565;
  hdma2d.LayerCfg[1].AlphaMode = DMA2D_NO_MODIF_ALPHA;
  hdma2d.LayerCfg[1].InputAlpha = 0;
  if (HAL_DMA2D_Init(&hdma2d) != HAL_OK)
  {
    Error_Handler();
  }
  if (HAL_DMA2D_ConfigLayer(&hdma2d, 1) != HAL_OK)
  {
    Error_Handler();
  }

}

static void MX_I2C3_Init(void)
{

  hi2c3.Instance = I2C3;
  hi2c3.Init.ClockSpeed = 400000;
  hi2c3.Init.DutyCycle = I2C_DUTYCYCLE_2;
  hi2c3.Init.OwnAddress1 = 0;
  hi2c3.Init.AddressingMode = I2C_ADDRESSINGMODE_7BIT;
  hi2c3.Init.DualAddressMode = I2C_DUALADDRESS_DISABLE;
  hi2c3.Init.OwnAddress2 = 0;
  hi2c3.Init.GeneralCallMode = I2C_GENERALCALL_DISABLE;
  hi2c3.Init.NoStretchMode = I2C_NOSTRETCH_DISABLE;
  if (HAL_I2C_Init(&hi2c3) != HAL_OK)
  {
    Error_Handler();
  }
  /** Configure Analogue filter
  */
  if (HAL_I2CEx_ConfigAnalogFilter(&hi2c3, I2C_ANALOGFILTER_ENABLE) != HAL_OK)
  {
    Error_Handler();
  }
  /** Configure Digital filter
  */
  if (HAL_I2CEx_ConfigDigitalFilter(&hi2c3, 0) != HAL_OK)
  {
    Error_Handler();
  }

}

static void MX_LTDC_Init(void)
{

  LTDC_LayerCfgTypeDef pLayerCfg = {0};
  LTDC_LayerCfgTypeDef pLayerCfg1 = {0};

  hltdc.Instance = LTDC;
  hltdc.Init.HSPolarity = LTDC_HSPOLARITY_AL;
  hltdc.Init.VSPolarity = LTDC_VSPOLARITY_AL;
  hltdc.Init.DEPolarity = LTDC_DEPOLARITY_AL;
  hltdc.Init.PCPolarity = LTDC_PCPOLARITY_IPC;
  hltdc.Init.HorizontalSync = 9;
  hltdc.Init.VerticalSync = 1;
  hltdc.Init.AccumulatedHBP = 29;
  hltdc.Init.AccumulatedVBP = 3;
  hltdc.Init.AccumulatedActiveW = 269;
  hltdc.Init.AccumulatedActiveH = 323;
  hltdc.Init.TotalWidth = 279;
  hltdc.Init.TotalHeigh = 327;
  hltdc.Init.Backcolor.Blue = 0;
  hltdc.Init.Backcolor.Green = 0;
  hltdc.Init.Backcolor.Red = 0;
  if (HAL_LTDC_Init(&hltdc) != HAL_OK)
  {
    Error_Handler();
  }
  pLayerCfg.WindowX0 = 0;
  pLayerCfg.WindowX1 = 240;
  pLayerCfg.WindowY0 = 0;
  pLayerCfg.WindowY1 = 320;
  pLayerCfg.PixelFormat = LTDC_PIXEL_FORMAT_RGB565;
  pLayerCfg.Alpha = 255;
  pLayerCfg.Alpha0 = 0;
  pLayerCfg.BlendingFactor1 = LTDC_BLENDING_FACTOR1_CA;
  pLayerCfg.BlendingFactor2 = LTDC_BLENDING_FACTOR2_CA;
  pLayerCfg.FBStartAdress = 0xD0000000;
  pLayerCfg.ImageWidth = 240;
  pLayerCfg.ImageHeight = 320;
  pLayerCfg.Backcolor.Blue = 0;
  pLayerCfg.Backcolor.Green = 0;
  pLayerCfg.Backcolor.Red = 0;
  if (HAL_LTDC_ConfigLayer(&hltdc, &pLayerCfg, 0) != HAL_OK)
  {
    Error_Handler();
  }
  pLayerCfg1.WindowX0 = 0;
  pLayerCfg1.WindowX1 = 240;
  pLayerCfg1.WindowY0 = 0;
  pLayerCfg1.WindowY1 = 320;
  pLayerCfg1.PixelFormat = LTDC_PIXEL_FORMAT_RGB565;
  pLayerCfg1.Alpha = 0;
  pLayerCfg1.Alpha0 = 0;
  pLayerCfg1.BlendingFactor1 = LTDC_BLENDING_FACTOR1_PAxCA;
  pLayerCfg1.BlendingFactor2 = LTDC_BLENDING_FACTOR2_PAxCA;
  pLayerCfg1.FBStartAdress = 0xD0025800;
  pLayerCfg1.ImageWidth = 240;
  pLayerCfg1.ImageHeight = 320;
  pLayerCfg1.Backcolor.Blue = 0;
  pLayerCfg1.Backcolor.Green = 0;
  pLayerCfg1.Backcolor.Red = 0;
  if (HAL_LTDC_ConfigLayer(&hltdc, &pLayerCfg1, 1) != HAL_OK)
  {
    Error_Handler();
  }
  /* USER CODE BEGIN LTDC_Init 2 */

    __HAL_LTDC_RELOAD_IMMEDIATE_CONFIG(&hltdc);

    __HAL_LTDC_LAYER_ENABLE(&hltdc, LTDC_LAYER_1);
    __HAL_LTDC_LAYER_ENABLE(&hltdc, LTDC_LAYER_2);
    HAL_LTDC_EnableDither(&hltdc);
    __HAL_LTDC_ENABLE(&hltdc);

  /* USER CODE END LTDC_Init 2 */

}

static void MX_SPI5_Init(void)
{

  /* SPI5 parameter configuration*/
  hspi5.Instance = SPI5;
  hspi5.Init.Mode = SPI_MODE_MASTER;
  hspi5.Init.Direction = SPI_DIRECTION_2LINES;
  hspi5.Init.DataSize = SPI_DATASIZE_8BIT;
  hspi5.Init.CLKPolarity = SPI_POLARITY_LOW;
  hspi5.Init.CLKPhase = SPI_PHASE_1EDGE;
  hspi5.Init.NSS = SPI_NSS_SOFT;
  hspi5.Init.BaudRatePrescaler = SPI_BAUDRATEPRESCALER_16;
  hspi5.Init.FirstBit = SPI_FIRSTBIT_MSB;
  hspi5.Init.TIMode = SPI_TIMODE_DISABLE;
  hspi5.Init.CRCCalculation = SPI_CRCCALCULATION_DISABLE;
  hspi5.Init.CRCPolynomial = 10;
  if (HAL_SPI_Init(&hspi5) != HAL_OK)
  {
    Error_Handler();
  }

}

static void MX_TIM2_Init(void)
{

  TIM_ClockConfigTypeDef sClockSourceConfig = {0};
  TIM_MasterConfigTypeDef sMasterConfig = {0};

  htim2.Instance = TIM2;
  htim2.Init.Prescaler = 0;
  htim2.Init.CounterMode = TIM_COUNTERMODE_UP;
  htim2.Init.Period = 4294967295;
  htim2.Init.ClockDivision = TIM_CLOCKDIVISION_DIV1;
  htim2.Init.AutoReloadPreload = TIM_AUTORELOAD_PRELOAD_ENABLE;
  if (HAL_TIM_Base_Init(&htim2) != HAL_OK)
  {
    Error_Handler();
  }
  sClockSourceConfig.ClockSource = TIM_CLOCKSOURCE_INTERNAL;
  if (HAL_TIM_ConfigClockSource(&htim2, &sClockSourceConfig) != HAL_OK)
  {
    Error_Handler();
  }
  sMasterConfig.MasterOutputTrigger = TIM_TRGO_UPDATE;
  sMasterConfig.MasterSlaveMode = TIM_MASTERSLAVEMODE_DISABLE;
  if (HAL_TIMEx_MasterConfigSynchronization(&htim2, &sMasterConfig) != HAL_OK)
  {
    Error_Handler();
  }
  /* USER CODE BEGIN TIM2_Init 2 */
  while(__HAL_TIM_GET_FLAG(&htim2,0x1EFF)){
  	  __HAL_TIM_CLEAR_FLAG(&htim2,0x1EFF);	// Clear all flags
  	}
  /* USER CODE END TIM2_Init 2 */

}

static void MX_TIM5_Init(void)
{

  TIM_ClockConfigTypeDef sClockSourceConfig = {0};
  TIM_MasterConfigTypeDef sMasterConfig = {0};

  htim5.Instance = TIM5;
  htim5.Init.Prescaler = 99;
  htim5.Init.CounterMode = TIM_COUNTERMODE_UP;
  htim5.Init.Period = 44;
  htim5.Init.ClockDivision = TIM_CLOCKDIVISION_DIV1;
  htim5.Init.AutoReloadPreload = TIM_AUTORELOAD_PRELOAD_DISABLE;
  if (HAL_TIM_Base_Init(&htim5) != HAL_OK)
  {
    Error_Handler();
  }
  sClockSourceConfig.ClockSource = TIM_CLOCKSOURCE_INTERNAL;
  if (HAL_TIM_ConfigClockSource(&htim5, &sClockSourceConfig) != HAL_OK)
  {
    Error_Handler();
  }
  sMasterConfig.MasterOutputTrigger = TIM_TRGO_UPDATE;
  sMasterConfig.MasterSlaveMode = TIM_MASTERSLAVEMODE_DISABLE;
  if (HAL_TIMEx_MasterConfigSynchronization(&htim5, &sMasterConfig) != HAL_OK)
  {
    Error_Handler();
  }
  /* USER CODE BEGIN TIM5_Init 2 */
  HAL_TIM_Base_Start_IT(&htim5);
  /* USER CODE END TIM5_Init 2 */

}

static void MX_USART1_UART_Init(void)
{

  huart1.Instance = USART1;
  huart1.Init.BaudRate = 115200;
  huart1.Init.WordLength = UART_WORDLENGTH_8B;
  huart1.Init.StopBits = UART_STOPBITS_1;
  huart1.Init.Parity = UART_PARITY_NONE;
  huart1.Init.Mode = UART_MODE_TX;
  huart1.Init.HwFlowCtl = UART_HWCONTROL_NONE;
  huart1.Init.OverSampling = UART_OVERSAMPLING_16;
  if (HAL_UART_Init(&huart1) != HAL_OK)
  {
    Error_Handler();
  }

}

static void MX_DMA_Init(void)
{

  /* DMA controller clock enable */
  __HAL_RCC_DMA2_CLK_ENABLE();

  /* DMA interrupt init */
  /* DMA2_Stream0_IRQn interrupt configuration */
  HAL_NVIC_SetPriority(DMA2_Stream0_IRQn, 0, 0);
  HAL_NVIC_EnableIRQ(DMA2_Stream0_IRQn);

}

/* FMC initialization function */
static void MX_FMC_Init(void)
{

  FMC_SDRAM_TimingTypeDef SdramTiming = {0};

  /** Perform the SDRAM1 memory initialization sequence
  */
  hsdram1.Instance = FMC_SDRAM_DEVICE;
  /* hsdram1.Init */
  hsdram1.Init.SDBank = FMC_SDRAM_BANK2;
  hsdram1.Init.ColumnBitsNumber = FMC_SDRAM_COLUMN_BITS_NUM_8;
  hsdram1.Init.RowBitsNumber = FMC_SDRAM_ROW_BITS_NUM_12;
  hsdram1.Init.MemoryDataWidth = FMC_SDRAM_MEM_BUS_WIDTH_16;
  hsdram1.Init.InternalBankNumber = FMC_SDRAM_INTERN_BANKS_NUM_4;
  hsdram1.Init.CASLatency = FMC_SDRAM_CAS_LATENCY_3;
  hsdram1.Init.WriteProtection = FMC_SDRAM_WRITE_PROTECTION_DISABLE;
  hsdram1.Init.SDClockPeriod = FMC_SDRAM_CLOCK_PERIOD_2;
  hsdram1.Init.ReadBurst = FMC_SDRAM_RBURST_DISABLE;
  hsdram1.Init.ReadPipeDelay = FMC_SDRAM_RPIPE_DELAY_1;
  /* SdramTiming */
  SdramTiming.LoadToActiveDelay = 2;
  SdramTiming.ExitSelfRefreshDelay = 7;
  SdramTiming.SelfRefreshTime = 4;
  SdramTiming.RowCycleDelay = 7;
  SdramTiming.WriteRecoveryTime = 3;
  SdramTiming.RPDelay = 2;
  SdramTiming.RCDDelay = 2;

  if (HAL_SDRAM_Init(&hsdram1, &SdramTiming) != HAL_OK)
  {
    Error_Handler( );
  }

  /* USER CODE BEGIN FMC_Init 2 */
  SDRAM_InitSequence();
  /* USER CODE END FMC_Init 2 */
}

static void MX_GPIO_Init(void)
{
  GPIO_InitTypeDef GPIO_InitStruct = {0};

  /* GPIO Ports Clock Enable */
  __HAL_RCC_GPIOF_CLK_ENABLE();
  __HAL_RCC_GPIOH_CLK_ENABLE();
  __HAL_RCC_GPIOC_CLK_ENABLE();
  __HAL_RCC_GPIOA_CLK_ENABLE();
  __HAL_RCC_GPIOB_CLK_ENABLE();
  __HAL_RCC_GPIOG_CLK_ENABLE();
  __HAL_RCC_GPIOE_CLK_ENABLE();
  __HAL_RCC_GPIOD_CLK_ENABLE();

  /*Configure GPIO pin Output Level */
  HAL_GPIO_WritePin(GPIOC, NCS_MEMS_SPI_Pin|CSX_Pin, GPIO_PIN_RESET);

  /*Configure GPIO pin Output Level */
  HAL_GPIO_WritePin(TEST_OUT_GPIO_Port, TEST_OUT_Pin, GPIO_PIN_RESET);

  /*Configure GPIO pin Output Level */
  HAL_GPIO_WritePin(GPIOD, RDX_Pin|WRX_DCX_Pin, GPIO_PIN_RESET);

  /*Configure GPIO pin Output Level */
  HAL_GPIO_WritePin(GPIOG, LED_GREEN_Pin|LED_RED_Pin, GPIO_PIN_RESET);

  /*Configure GPIO pins : NCS_MEMS_SPI_Pin CSX_Pin */
  GPIO_InitStruct.Pin = NCS_MEMS_SPI_Pin|CSX_Pin;
  GPIO_InitStruct.Mode = GPIO_MODE_OUTPUT_PP;
  GPIO_InitStruct.Pull = GPIO_NOPULL;
  GPIO_InitStruct.Speed = GPIO_SPEED_FREQ_LOW;
  HAL_GPIO_Init(GPIOC, &GPIO_InitStruct);

  /*Configure GPIO pin : BLUE_BTN_Pin */
  GPIO_InitStruct.Pin = BLUE_BTN_Pin;
  GPIO_InitStruct.Mode = GPIO_MODE_INPUT;
  GPIO_InitStruct.Pull = GPIO_NOPULL;
  HAL_GPIO_Init(BLUE_BTN_GPIO_Port, &GPIO_InitStruct);

  /*Configure GPIO pin : TEST_OUT_Pin */
  GPIO_InitStruct.Pin = TEST_OUT_Pin;
  GPIO_InitStruct.Mode = GPIO_MODE_OUTPUT_PP;
  GPIO_InitStruct.Pull = GPIO_NOPULL;
  GPIO_InitStruct.Speed = GPIO_SPEED_FREQ_LOW;
  HAL_GPIO_Init(TEST_OUT_GPIO_Port, &GPIO_InitStruct);

  /*Configure GPIO pin : TE_Pin */
  GPIO_InitStruct.Pin = TE_Pin;
  GPIO_InitStruct.Mode = GPIO_MODE_INPUT;
  GPIO_InitStruct.Pull = GPIO_NOPULL;
  HAL_GPIO_Init(TE_GPIO_Port, &GPIO_InitStruct);

  /*Configure GPIO pins : RDX_Pin WRX_DCX_Pin */
  GPIO_InitStruct.Pin = RDX_Pin|WRX_DCX_Pin;
  GPIO_InitStruct.Mode = GPIO_MODE_OUTPUT_PP;
  GPIO_InitStruct.Pull = GPIO_NOPULL;
  GPIO_InitStruct.Speed = GPIO_SPEED_FREQ_LOW;
  HAL_GPIO_Init(GPIOD, &GPIO_InitStruct);

  /*Configure GPIO pins : LED_GREEN_Pin LED_RED_Pin */
  GPIO_InitStruct.Pin = LED_GREEN_Pin|LED_RED_Pin;
  GPIO_InitStruct.Mode = GPIO_MODE_OUTPUT_PP;
  GPIO_InitStruct.Pull = GPIO_NOPULL;
  GPIO_InitStruct.Speed = GPIO_SPEED_FREQ_LOW;
  HAL_GPIO_Init(GPIOG, &GPIO_InitStruct);

}

void Error_Handler(void)
{
  /* USER CODE BEGIN Error_Handler_Debug */
  /* User can add his own implementation to report the HAL error return state */

	HAL_GPIO_WritePin(LED_GREEN_GPIO_Port,LED_GREEN_Pin,SET);
	HAL_GPIO_WritePin(LED_RED_GPIO_Port,LED_RED_Pin,RESET);
while(1){
	HAL_Delay(100);
	HAL_GPIO_TogglePin(LED_GREEN_GPIO_Port,LED_GREEN_Pin );
	HAL_GPIO_TogglePin(LED_RED_GPIO_Port,LED_RED_Pin );

}
  /* USER CODE END Error_Handler_Debug */
}

/************************ (C) COPYRIGHT STMicroelectronics *****END OF FILE****/
